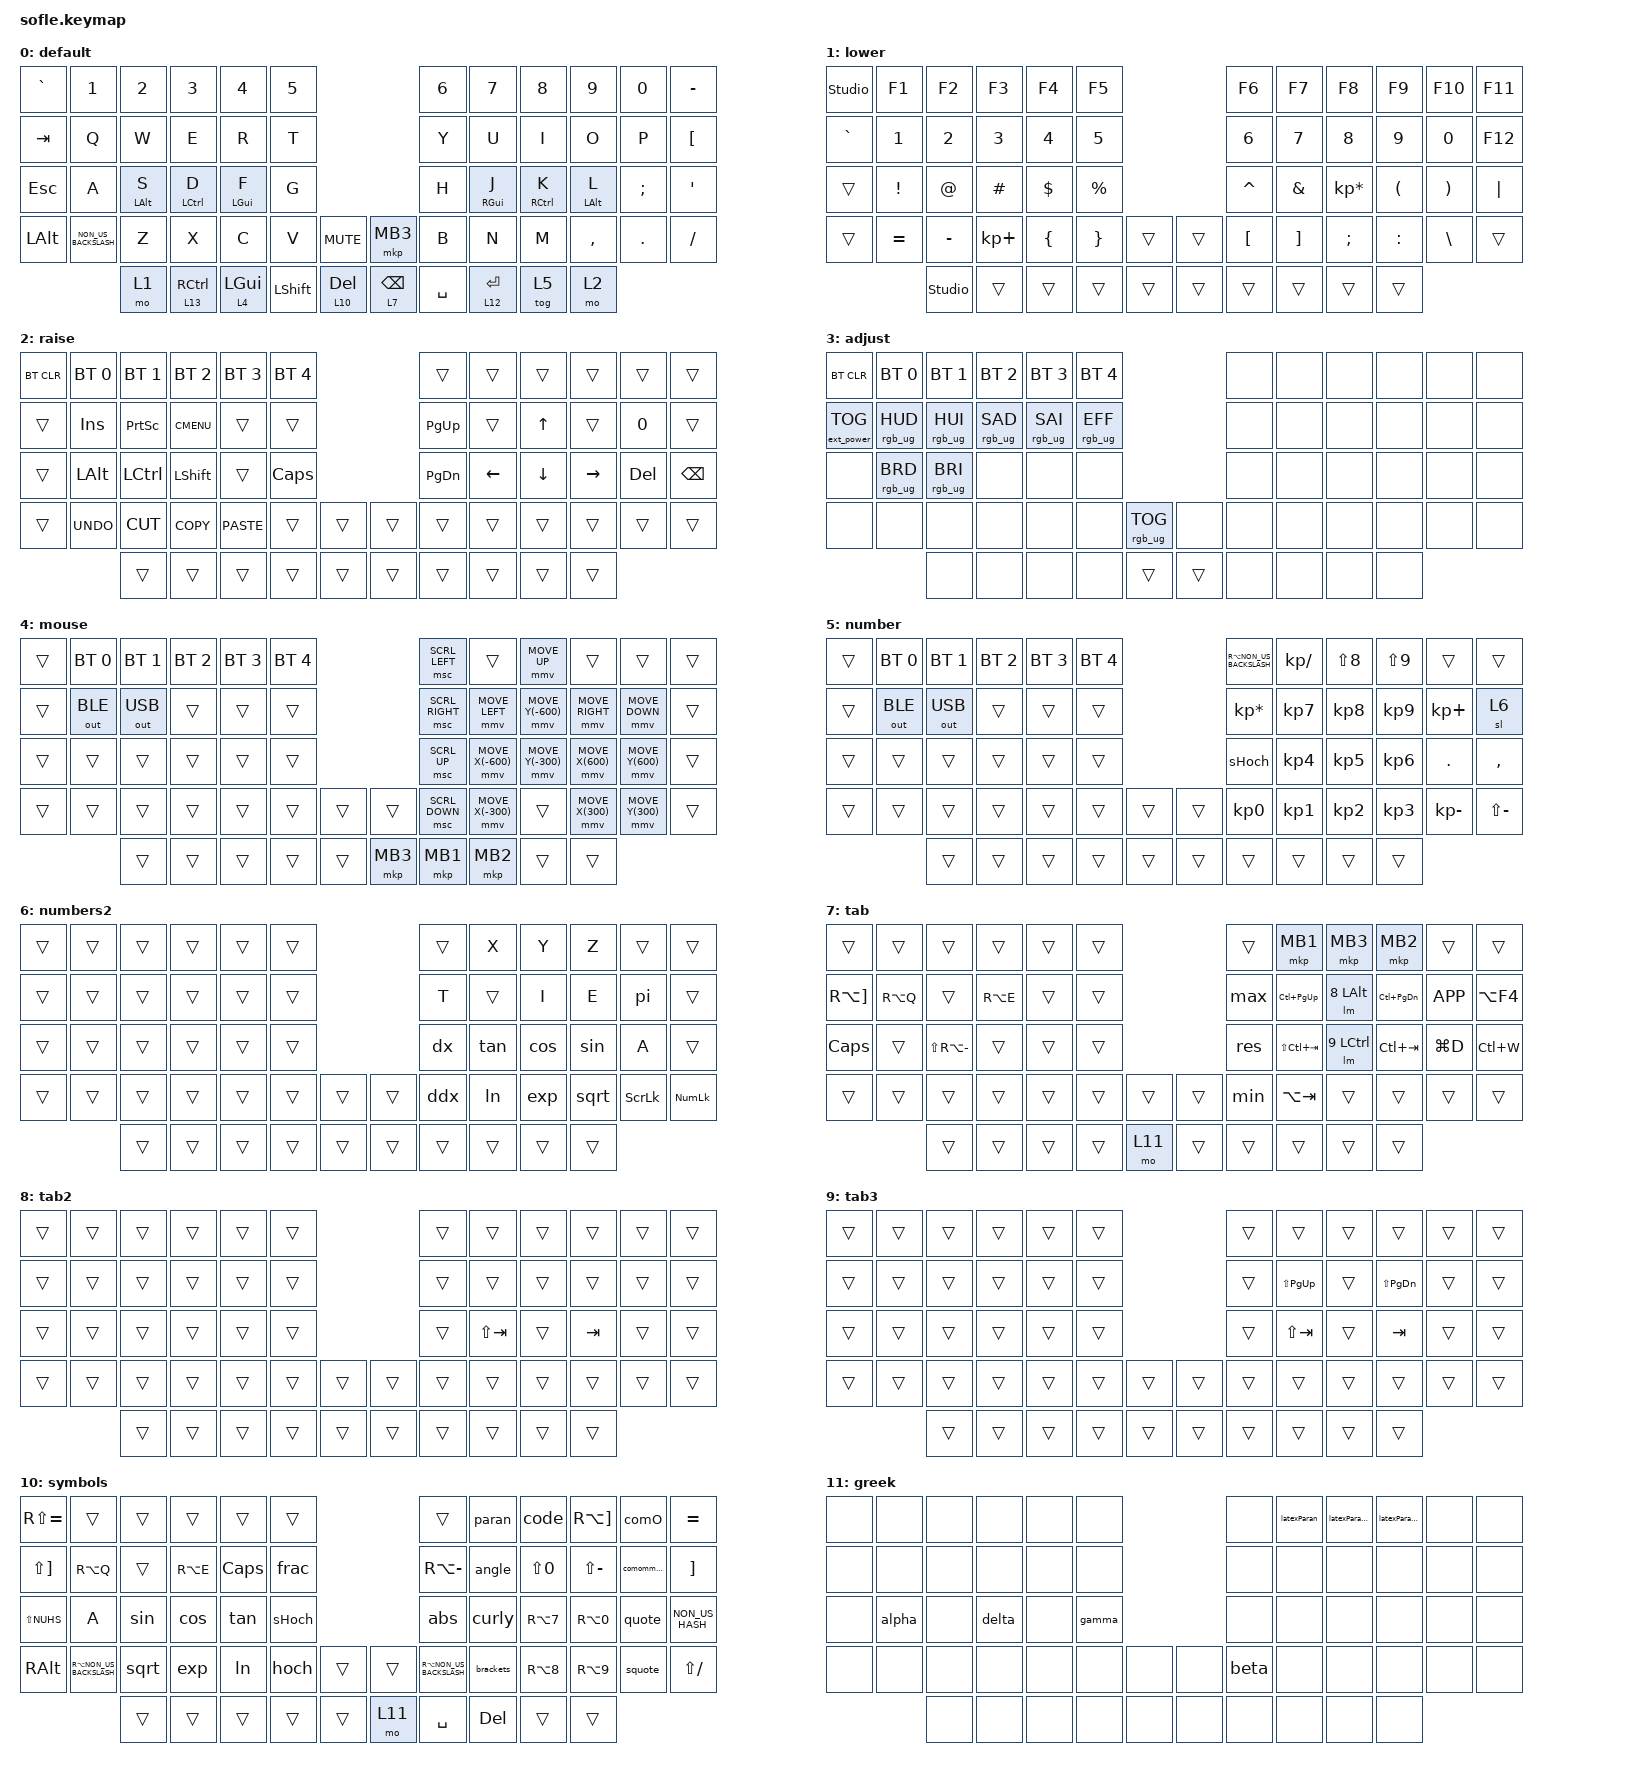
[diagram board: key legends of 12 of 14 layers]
/*
 * Copyright (c) 2020 The ZMK Contributors
 *
 * SPDX-License-Identifier: MIT
 */

#define ZMK_POINTING_DEFAULT_MOVE_VAL 1500  // default: 600
#define ZMK_POINTING_DEFAULT_SCRL_VAL 20    // default: 10

#include <behaviors.dtsi>
#include <dt-bindings/zmk/bt.h>
#include <dt-bindings/zmk/ext_power.h>
#include <dt-bindings/zmk/keys.h>
#include <dt-bindings/zmk/outputs.h>
#include <dt-bindings/zmk/pointing.h>
#include <dt-bindings/zmk/rgb.h>

#define BASE 0
#define LOWER 1
#define RAISE 2
#define ADJUST 3

&lt { flavor = "balanced"; };

/ {
    // Activate ADJUST layer by pressing raise and lower

    conditional_layers {
        compatible = "zmk,conditional-layers";

        adjust_layer {
            if-layers = <1 2>;
            then-layer = <3>;
        };
    };

    macros {
        lm: lm {
            compatible = "zmk,behavior-macro-two-param";
            #binding-cells = <2>;
            bindings =
                <&macro_param_1to1>,
                <&macro_press>,
                <&mo MACRO_PLACEHOLDER &macro_param_2to1>,
                <&macro_press>,
                <&kp MACRO_PLACEHOLDER>,
                <&macro_pause_for_release>,
                <&macro_param_2to1>,
                <&macro_release>,
                <&kp MACRO_PLACEHOLDER &macro_param_1to1>,
                <&macro_release>,
                <&mo MACRO_PLACEHOLDER>;

            label = "LM";
        };

        curly: curly {
            compatible = "zmk,behavior-macro";
            #binding-cells = <0>;
            bindings = <&kp RA(N7) &kp RA(N0) &kp LEFT>;
            label = "CURLY";
        };

        paran: paran {
            compatible = "zmk,behavior-macro";
            #binding-cells = <0>;
            bindings = <&kp LS(N8) &kp LS(N9) &kp LEFT>;
            label = "PARAN";
        };

        angle: angle {
            compatible = "zmk,behavior-macro";
            #binding-cells = <0>;
            bindings = <&kp NON_US_BACKSLASH &kp LS(NON_US_BACKSLASH) &kp LEFT>;
            label = "angle";
        };

        brackets: brackets {
            compatible = "zmk,behavior-macro";
            #binding-cells = <0>;
            bindings = <&kp RA(N8) &kp RA(N9) &kp LEFT>;
            label = "BRACKETS";
        };

        abs: abs {
            compatible = "zmk,behavior-macro";
            #binding-cells = <0>;
            bindings = <&kp RA(NON_US_BACKSLASH) &kp RA(NON_US_BACKSLASH) &kp LEFT>;
            label = "ABS";
        };

        comO: comO {
            compatible = "zmk,behavior-macro";
            #binding-cells = <0>;
            bindings = <&kp LS(N7) &kp LS(RIGHT_BRACKET)>;
            label = "COMO";
        };

        comommentClose: comC {
            compatible = "zmk,behavior-macro";
            #binding-cells = <0>;
            bindings = <&kp LS(RIGHT_BRACKET) &kp LS(N7)>;
            label = "COMC";
        };

        code: code {
            compatible = "zmk,behavior-macro";
            #binding-cells = <0>;
            bindings = <&kp LS(EQUAL) &kp LS(EQUAL) &kp LS(EQUAL) &kp SPACE>;
            label = "CODE";
        };

        quote: quote {
            compatible = "zmk,behavior-macro";
            #binding-cells = <0>;
            bindings = <&kp LS(N2) &kp LS(N2) &kp LEFT>;
            label = "QUOTE";
        };

        squote: squote {
            compatible = "zmk,behavior-macro";
            #binding-cells = <0>;
            bindings = <&kp LS(NON_US_HASH) &kp LS(NON_US_HASH) &kp LEFT>;
            label = "SQUOTE";
        };

        max: max {
            compatible = "zmk,behavior-macro";
            #binding-cells = <0>;
            bindings = <&kp LA(SPACE) &kp X>;
            label = "MAX";
        };

        min: min {
            compatible = "zmk,behavior-macro";
            #binding-cells = <0>;
            bindings = <&kp LA(SPACE) &kp N>;
            label = "MIN";
        };

        res: res {
            compatible = "zmk,behavior-macro";
            #binding-cells = <0>;
            bindings = <&kp LA(SPACE) &kp R>;
            label = "RES";
        };

        sin: sin {
            compatible = "zmk,behavior-macro";
            #binding-cells = <0>;
            bindings = <&kp S &kp I &kp N &kp LS(N8) &kp LS(N9) &kp LEFT>;
            label = "SIN";
        };

        cos: cos {
            compatible = "zmk,behavior-macro";
            #binding-cells = <0>;
            bindings = <&kp C &kp O &kp S &kp LS(N8) &kp LS(N9) &kp LEFT>;
            label = "COS";
        };

        tan: tan {
            compatible = "zmk,behavior-macro";
            #binding-cells = <0>;
            bindings = <&kp T &kp A &kp N &kp LS(N8) &kp LS(N9) &kp LEFT>;
            label = "TAN";
        };

        sqrt: sqrt {
            compatible = "zmk,behavior-macro";
            #binding-cells = <0>;
            bindings = <&kp S &kp Q &kp R &kp T &kp LS(N8) &kp LS(N9) &kp LEFT>;
            label = "SQRT";
        };

        hoch: hoch {
            compatible = "zmk,behavior-macro";
            #binding-cells = <0>;
            bindings = <&kp GRAVE &kp LS(N8) &kp LS(N9) &kp LEFT>;
            label = "HOCH";
        };

        exp: exp {
            compatible = "zmk,behavior-macro";
            #binding-cells = <0>;
            bindings = <&kp E &kp X &kp P &kp LS(N8) &kp LS(N9) &kp LEFT>;
            label = "EXP";
        };

        ln: ln {
            compatible = "zmk,behavior-macro";
            #binding-cells = <0>;
            bindings = <&kp L &kp N &kp LS(N8) &kp LS(N9) &kp LEFT>;
            label = "LN";
        };

        latexParanOpen: latexParanOpen {
            compatible = "zmk,behavior-macro";
            #binding-cells = <0>;
            bindings = <&kp RA(MINUS) &kp L &kp E &kp F &kp T &kp LS(N8)>;
            label = "LATEXPARAN";
        };

        latexParanClose: latexParanClose {
            compatible = "zmk,behavior-macro";
            #binding-cells = <0>;
            bindings = <&kp RA(MINUS) &kp R &kp I &kp G &kp H &kp T &kp LS(N9)>;
            label = "LATEXPARANCLOSE";
        };

        latexParan: latexParan {
            compatible = "zmk,behavior-macro";
            #binding-cells = <0>;
            bindings = <&kp RA(MINUS) &kp L &kp E &kp F &kp T &kp LS(N8) &kp RA(MINUS) &kp R &kp I &kp G &kp H &kp T &kp LS(N9) &kp LEFT_ARROW &kp LEFT_ARROW &kp LEFT_ARROW &kp LEFT_ARROW &kp LEFT &kp LEFT_ARROW &kp LEFT_ARROW>;
            label = "LATEXPARAN";
        };

        alpha: alpha {
            compatible = "zmk,behavior-macro";
            #binding-cells = <0>;
            bindings = <&kp RA(MINUS) &kp A &kp L &kp P &kp H &kp A>;
            label = "ALPHA";
        };

        beta: beta {
            compatible = "zmk,behavior-macro";
            #binding-cells = <0>;
            bindings = <&kp RA(MINUS) &kp B &kp E &kp T &kp A>;
            label = "BETA";
        };

        gamma: gamma {
            compatible = "zmk,behavior-macro";
            #binding-cells = <0>;
            bindings = <&kp RA(MINUS) &kp G &kp A &kp M &kp M &kp A>;
            label = "GAMMA";
        };

        delta: delta {
            compatible = "zmk,behavior-macro";
            #binding-cells = <0>;
            bindings = <&kp RA(MINUS) &kp D &kp E &kp L &kp T &kp A>;
            label = "DELTA";
        };

        sHoch: sHoch {
            compatible = "zmk,behavior-macro";
            #binding-cells = <0>;
            bindings = <&kp GRAVE &kp SPACE>;
            label = "SHOCH";
        };

        frac: frac {
            compatible = "zmk,behavior-macro";
            #binding-cells = <0>;
            bindings = <&kp RA(MINUS) &kp F &kp R &kp A &kp C &kp RA(N7) &kp RA(N0) &kp RA(N7) &kp RA(N0) &kp LEFT &kp LEFT_ARROW &kp LEFT_ARROW>;
            label = "FRAC";
        };

        pi: pi {
            compatible = "zmk,behavior-macro";
            #binding-cells = <0>;
            bindings = <&kp P &kp I>;
            label = "PI";
        };

        dx: dx {
            compatible = "zmk,behavior-macro";
            #binding-cells = <0>;
            bindings = <&kp D &kp X>;
            label = "DX";
        };

        ddx: ddx {
            compatible = "zmk,behavior-macro";
            #binding-cells = <0>;
            bindings = <&kp D &kp LS(N7) &kp D &kp X>;
            label = "DDX";
        };
    };

    behaviors {
        MoTapHp: MoTapHp {
            compatible = "zmk,behavior-hold-tap";
            label = "MOTAPHP";
            bindings = <&mo>, <&kp>;

            #binding-cells = <2>;
            tapping-term-ms = <280>;
            quick-tap-ms = <175>;
            flavor = "hold-preferred";
            hold-trigger-key-positions = <20 32 18 30 44 19 31 33 34 7 9 8 21 23 35 54 24 12 13 15 26 45>;
        };

        HRM_L: HRM_L {
            compatible = "zmk,behavior-hold-tap";
            label = "HRM_L";
            bindings = <&kp>, <&kp>;

            #binding-cells = <2>;
            tapping-term-ms = <280>;
            quick-tap-ms = <175>;
            require-prior-idle-ms = <150>;
            flavor = "balanced";
            hold-trigger-key-positions = <57 56 55 53 0 1 2 3 4 5 12 13 14 15 16 17 24 25 26 27 28 29 36 37 38 39 40 41 42>;
            hold-trigger-on-release;
        };

        HRM_R: HRM_R {
            compatible = "zmk,behavior-hold-tap";
            label = "HRM_R";
            bindings = <&kp>, <&kp>;

            #binding-cells = <2>;
            tapping-term-ms = <280>;
            quick-tap-ms = <175>;
            require-prior-idle-ms = <150>;
            flavor = "balanced";
            hold-trigger-key-positions = <57 56 55 53 6 7 8 9 10 11 18 19 20 21 22 23 30 31 32 33 34 35 43 44 45 46 47 48 49>;
            hold-trigger-on-release;
        };

        MoTap: MoTap {
            compatible = "zmk,behavior-hold-tap";
            label = "MOTAP";
            bindings = <&mo>, <&kp>;

            #binding-cells = <2>;
            tapping-term-ms = <280>;
            quick-tap-ms = <175>;
            require-prior-idle-ms = <150>;
            flavor = "balanced";
        };

        nav_word: nav_word {
            compatible = "zmk,behavior-auto-layer";
            #binding-cells = <1>;
            continue-list = <LEFT DOWN UP RIGHT PG_DN PG_UP HOME END TAB>;
            ignore-modifiers;
        };

        navWord: navWord {
            compatible = "zmk,behavior-hold-tap";
            label = "NAVWORD";
            bindings = <&nav_word>, <&kp>;

            #binding-cells = <2>;
            tapping-term-ms = <280>;
            quick-tap-ms = <175>;
            require-prior-idle-ms = <150>;
            flavor = "balanced";
        };

        ms_word: ms_word {
            compatible = "zmk,behavior-auto-layer";
            #binding-cells = <1>;
            continue-list = <LEFT DOWN UP RIGHT PG_DN PG_UP HOME END TAB>;
            ignore-modifiers;
        };

        msWord: msWord {
            compatible = "zmk,behavior-hold-tap";
            label = "MSWORD";
            bindings = <&ms_word>, <&kp>;

            #binding-cells = <2>;
            tapping-term-ms = <280>;
            quick-tap-ms = <175>;
            require-prior-idle-ms = <150>;
            flavor = "balanced";
        };
    };

    combos { compatible = "zmk,combos"; };

    keymap {
        compatible = "zmk,keymap";

        default_layer {
            label = "default";

            // ------------------------------------------------------------------------------------------------------------
            // |   `   |  1  |  2  |  3   |  4   |  5   |                   |  6   |  7    |  8    |  9   |   0   |       |
            // |  ESC  |  Q  |  W  |  E   |  R   |  T   |                   |  Y   |  U    |  I    |  O   |   P   | BKSPC |
            // |  TAB  |  A  |  S  |  D   |  F   |  G   |                   |  H   |  J    |  K    |  L   |   ;   |   '   |
            // | SHIFT |  Z  |  X  |  C   |  V   |  B   |  MUTE  |  |       |  N   |  M    |  ,    |  .   |   /   | SHIFT |
            //               | GUI | ALT  | CTRL | LOWER|  ENTER |  | SPACE | RAISE| CTRL  | ALT   | GUI  |

            bindings = <
&kp GRAVE     &kp N1                &kp N2             &kp N3           &kp N4             &kp N5                                                 &kp N6     &kp N7              &kp N8          &kp N9             &kp N0         &kp MINUS
&kp TAB       &kp Q                 &kp W              &kp E            &kp R              &kp T                                                  &kp Y      &kp U               &kp I           &kp O              &kp P          &kp LEFT_BRACKET
&kp ESC       &kp A                 &HRM_R LEFT_ALT S  &HRM_R LCTRL D   &HRM_R LEFT_GUI F  &kp G                                                  &kp H      &HRM_L RIGHT_GUI J  &HRM_L RCTRL K  &HRM_L LEFT_ALT L  &kp SEMICOLON  &kp SQT
&kp LEFT_ALT  &kp NON_US_BACKSLASH  &kp Z              &kp X            &kp C              &kp V           &kp K_MUTE       &mkp MB3              &kp B      &kp N               &kp M           &kp COMMA          &kp PERIOD     &kp SLASH
                                    &mo 1              &MoTap 13 RCTRL  &MoTap 4 LGUI      &kp LEFT_SHIFT  &MoTap 10 DEL    &MoTapHp 7 BACKSPACE  &kp SPACE  &MoTap 12 ENTER     &tog 5          &mo 2
            >;

            sensor-bindings =
                <&inc_dec_kp C_VOLUME_DOWN C_VOL_UP>,
                <&inc_dec_kp K_SCROLL_UP K_SCROLL_DOWN>;
        };

        lower_layer {
            label = "lower";

            // TODO: Some binds are waiting for shifted keycode support.
            // ------------------------------------------------------------------------------------------------------------
            // |       |  F1 |  F2 |  F3  |  F4  |  F5  |                   |  F6  |  F7   |  F8   |  F9  |  F10  |  F11  |
            // |   `   |  1  |  2  |  3   |  4   |  5   |                   |  6   |  7    |  8    |  9   |   0   |  F12  |
            // |       |  !  |  @  |  #   |  $   |  %   |                   |  ^   |  &    |  *    |  (   |   )   |   |   |
            // |       |  =  |  -  |  +   |  {   |  }   |        |  |       |  [   |  ]    |  ;    |  :   |   \   |       |
            //               |     |      |      |      |        |  |       |      |       |       |      |

            bindings = <
&studio_unlock  &kp F1     &kp F2          &kp F3       &kp F4    &kp F5                       &kp F6     &kp F7    &kp F8           &kp F9     &kp F10   &kp F11
&kp GRAVE       &kp N1     &kp N2          &kp N3       &kp N4    &kp N5                       &kp N6     &kp N7    &kp N8           &kp N9     &kp N0    &kp F12
&trans          &kp EXCL   &kp AT          &kp HASH     &kp DLLR  &kp PRCNT                    &kp CARET  &kp AMPS  &kp KP_MULTIPLY  &kp LPAR   &kp RPAR  &kp PIPE
&trans          &kp EQUAL  &kp MINUS       &kp KP_PLUS  &kp LBRC  &kp RBRC   &trans    &trans  &kp LBKT   &kp RBKT  &kp SEMI         &kp COLON  &kp BSLH  &trans
                           &studio_unlock  &trans       &trans    &trans     &trans    &trans  &trans     &trans    &trans           &trans
            >;

            sensor-bindings = <&inc_dec_kp C_VOL_UP C_VOL_DN &inc_dec_kp PG_UP PG_DN>;
        };

        raise_layer {
            label = "raise";

            // ------------------------------------------------------------------------------------------------------------
            // | BTCLR | BT1  | BT2  |  BT3  |  BT4  |  BT5 |                |      |      |       |      |       |       |
            // |       | INS  | PSCR | GUI   |       |      |                | PGUP |      |   ^   |      |       |       |
            // |       | ALT  | CTRL | SHIFT |       | CAPS |                | PGDN |   <- |   v   |  ->  |  DEL  | BKSPC |
            // |       | UNDO | CUT  | COPY  | PASTE |      |      |  |      |      |      |       |      |       |       |
            //                |      |       |       |      |      |  |      |      |      |       |      |

            bindings = <
&bt BT_CLR  &bt BT_SEL 0  &bt BT_SEL 1  &bt BT_SEL 2  &bt BT_SEL 3  &bt BT_SEL 4                    &trans     &trans    &trans    &trans     &trans   &trans
&trans      &kp INS       &kp PSCRN     &kp K_CMENU   &trans        &trans                          &kp PG_UP  &trans    &kp UP    &trans     &kp N0   &trans
&trans      &kp LALT      &kp LCTRL     &kp LSHFT     &trans        &kp CLCK                        &kp PG_DN  &kp LEFT  &kp DOWN  &kp RIGHT  &kp DEL  &kp BSPC
&trans      &kp K_UNDO    &kp K_CUT     &kp K_COPY    &kp K_PASTE   &trans        &trans    &trans  &trans     &trans    &trans    &trans     &trans   &trans
                          &trans        &trans        &trans        &trans        &trans    &trans  &trans     &trans    &trans    &trans
            >;

            sensor-bindings = <&inc_dec_kp C_VOL_UP C_VOL_DN &inc_dec_kp PG_UP PG_DN>;
        };

        adjust_layer {
            // ----------------------------------------------------------------------------------------------------------------------------
            // | BTCLR  |  BT1    |  BT2    |   BT3   |   BT4   |   BT5   |                  |      |      |       |      |       |       |
            // | EXTPWR | RGB_HUD | RGB_HUI | RGB_SAD | RGB_SAI | RGB_EFF |                  |      |      |       |      |       |       |
            // |        | RGB_BRD | RGB_BRI |         |         |         |                  |      |      |       |      |       |       |
            // |        |         |         |         |         |         | RGB_TOG | |      |      |      |       |      |       |       |
            //                    |         |         |         |         |         | |      |      |      |       |      |

            label = "adjust";
            bindings = <
&bt BT_CLR         &bt BT_SEL 0     &bt BT_SEL 1     &bt BT_SEL 2     &bt BT_SEL 3     &bt BT_SEL 4                                &none  &none  &none  &none  &none  &none
&ext_power EP_TOG  &rgb_ug RGB_HUD  &rgb_ug RGB_HUI  &rgb_ug RGB_SAD  &rgb_ug RGB_SAI  &rgb_ug RGB_EFF                             &none  &none  &none  &none  &none  &none
&none              &rgb_ug RGB_BRD  &rgb_ug RGB_BRI  &none            &none            &none                                       &none  &none  &none  &none  &none  &none
&none              &none            &none            &none            &none            &none            &rgb_ug RGB_TOG    &none   &none  &none  &none  &none  &none  &none
                                    &none            &none            &none            &none            &trans             &trans  &none  &none  &none  &none
            >;
        };

        mouse {
            bindings = <
&trans  &bt BT_SEL 0  &bt BT_SEL 1  &bt BT_SEL 2  &bt BT_SEL 3  &bt BT_SEL 4                      &msc SCRL_LEFT   &trans             &mmv MOVE_UP       &trans            &trans            &trans
&trans  &out OUT_BLE  &out OUT_USB  &trans        &trans        &trans                            &msc SCRL_RIGHT  &mmv MOVE_LEFT     &mmv MOVE_Y(-600)  &mmv MOVE_RIGHT   &mmv MOVE_DOWN    &trans
&trans  &trans        &trans        &trans        &trans        &trans                            &msc SCRL_UP     &mmv MOVE_X(-600)  &mmv MOVE_Y(-300)  &mmv MOVE_X(600)  &mmv MOVE_Y(600)  &trans
&trans  &trans        &trans        &trans        &trans        &trans        &trans    &trans    &msc SCRL_DOWN   &mmv MOVE_X(-300)  &trans             &mmv MOVE_X(300)  &mmv MOVE_Y(300)  &trans
                      &trans        &trans        &trans        &trans        &trans    &mkp MB3  &mkp MB1         &mkp MB2           &trans             &trans
            >;

            label = "mouse";
        };

        number {
            label = "number";
            bindings = <
&trans  &bt BT_SEL 0  &bt BT_SEL 1  &bt BT_SEL 2  &bt BT_SEL 3  &bt BT_SEL 4                    &kp RA(NON_US_BACKSLASH)  &kp KP_DIVIDE    &kp LS(N8)       &kp LS(N9)       &trans        &trans
&trans  &out OUT_BLE  &out OUT_USB  &trans        &trans        &trans                          &kp KP_MULTIPLY           &kp KP_NUMBER_7  &kp KP_NUMBER_8  &kp KP_NUMBER_9  &kp KP_PLUS   &sl 6
&trans  &trans        &trans        &trans        &trans        &trans                          &sHoch                    &kp KP_NUMBER_4  &kp KP_NUMBER_5  &kp KP_NUMBER_6  &kp PERIOD    &kp COMMA
&trans  &trans        &trans        &trans        &trans        &trans        &trans    &trans  &kp KP_NUMBER_0           &kp KP_NUMBER_1  &kp KP_NUMBER_2  &kp KP_NUMBER_3  &kp KP_MINUS  &kp LS(MINUS)
                      &trans        &trans        &trans        &trans        &trans    &trans  &trans                    &trans           &trans           &trans
            >;
        };

        numbers2 {
            bindings = <
&trans  &trans  &trans  &trans  &trans  &trans                    &trans  &kp X   &kp Y   &kp Z   &trans          &trans
&trans  &trans  &trans  &trans  &trans  &trans                    &kp T   &trans  &kp I   &kp E   &pi             &trans
&trans  &trans  &trans  &trans  &trans  &trans                    &dx     &tan    &cos    &sin    &kp A           &trans
&trans  &trans  &trans  &trans  &trans  &trans  &trans    &trans  &ddx    &ln     &exp    &sqrt   &kp SCROLLLOCK  &kp KP_NUM
                &trans  &trans  &trans  &trans  &trans    &trans  &trans  &trans  &trans  &trans
            >;

            label = "numbers2";
        };

        tab {
            bindings = <
&trans                 &trans     &trans             &trans     &trans  &trans                    &trans  &mkp MB1         &mkp MB3     &mkp MB2           &trans     &trans
&kp RA(RIGHT_BRACKET)  &kp RA(Q)  &trans             &kp RA(E)  &trans  &trans                    &max    &kp LC(PG_UP)    &lm 8 LALT   &kp LC(PAGE_DOWN)  &kp K_APP  &kp LA(F4)
&kp CAPS               &trans     &kp LS(RA(MINUS))  &trans     &trans  &trans                    &res    &kp LS(LC(TAB))  &lm 9 LCTRL  &kp LC(TAB)        &kp LG(D)  &kp LC(W)
&trans                 &trans     &trans             &trans     &trans  &trans  &trans    &trans  &min    &kp LA(TAB)      &trans       &trans             &trans     &trans
                                  &trans             &trans     &trans  &trans  &mo 11    &trans  &trans  &trans           &trans       &trans
            >;

            label = "tab";
        };

        tab2 {
            bindings = <
&trans  &trans  &trans  &trans  &trans  &trans                    &trans  &trans       &trans  &trans   &trans  &trans
&trans  &trans  &trans  &trans  &trans  &trans                    &trans  &trans       &trans  &trans   &trans  &trans
&trans  &trans  &trans  &trans  &trans  &trans                    &trans  &kp LS(TAB)  &trans  &kp TAB  &trans  &trans
&trans  &trans  &trans  &trans  &trans  &trans  &trans    &trans  &trans  &trans       &trans  &trans   &trans  &trans
                &trans  &trans  &trans  &trans  &trans    &trans  &trans  &trans       &trans  &trans
            >;

            label = "tab2";
        };

        tab3 {
            label = "tab3";
            bindings = <
&trans  &trans  &trans  &trans  &trans  &trans                    &trans  &trans         &trans  &trans         &trans  &trans
&trans  &trans  &trans  &trans  &trans  &trans                    &trans  &kp LS(PG_UP)  &trans  &kp LS(PG_DN)  &trans  &trans
&trans  &trans  &trans  &trans  &trans  &trans                    &trans  &kp LS(TAB)    &trans  &kp TAB        &trans  &trans
&trans  &trans  &trans  &trans  &trans  &trans  &trans    &trans  &trans  &trans         &trans  &trans         &trans  &trans
                &trans  &trans  &trans  &trans  &trans    &trans  &trans  &trans         &trans  &trans
            >;
        };

        symbols {
            bindings = <
&kp RS(EQUAL)          &trans                    &trans  &trans     &trans    &trans                    &trans                    &paran     &code       &kp RA(RIGHT_BRACKET)  &comO            &kp EQUAL
&kp LS(RIGHT_BRACKET)  &kp RA(Q)                 &trans  &kp RA(E)  &kp CAPS  &frac                     &kp RA(MINUS)             &angle     &kp LS(N0)  &kp LS(MINUS)          &comommentClose  &kp RIGHT_BRACKET
&kp LS(NUHS)           &kp A                     &sin    &cos       &tan      &sHoch                    &abs                      &curly     &kp RA(N7)  &kp RA(N0)             &quote           &kp NON_US_HASH
&kp RALT               &kp RA(NON_US_BACKSLASH)  &sqrt   &exp       &ln       &hoch   &trans    &trans  &kp RA(NON_US_BACKSLASH)  &brackets  &kp RA(N8)  &kp RA(N9)             &squote          &kp LS(SLASH)
                                                 &trans  &trans     &trans    &trans  &trans    &mo 11  &kp SPACE                 &kp DEL    &trans      &trans
            >;

            label = "symbols";
        };

        greek {
            bindings = <
&none  &none   &none  &none   &none  &none                   &none  &latexParan  &latexParanOpen  &latexParanClose  &none  &none
&none  &none   &none  &none   &none  &none                   &none  &none        &none            &none             &none  &none
&none  &alpha  &none  &delta  &none  &gamma                  &none  &none        &none            &none             &none  &none
&none  &none   &none  &none   &none  &none   &none    &none  &beta  &none        &none            &none             &none  &none
               &none  &none   &none  &none   &none    &none  &none  &none        &none            &none
            >;

            label = "greek";
        };

        nav {
            bindings = <
&trans  &trans  &trans  &trans  &trans  &trans                    &trans     &kp LC(HOME)   &kp K_APPLICATION  &kp LC(END)    &trans     &kp INS
&trans  &trans  &trans  &trans  &trans  &trans                    &kp HOME   &kp LC(LEFT)   &kp UP_ARROW       &kp LC(RIGHT)  &kp END    &kp LC(V)
&trans  &trans  &trans  &trans  &trans  &trans                    &kp PG_UP  &kp LEFT       &kp LS(TAB)        &kp RIGHT      &kp DOWN   &kp TAB
&trans  &trans  &trans  &trans  &trans  &trans  &trans    &trans  &kp PG_DN  &kp BACKSPACE  &kp DEL            &kp LC(A)      &kp LC(X)  &kp LC(C)
                &trans  &trans  &trans  &trans  &trans    &trans  &trans     &trans         &trans             &trans
            >;

            label = "nav";
        };

        media {
            bindings = <
&trans  &trans      &trans      &trans            &trans      &trans                          &trans  &kp F10  &kp F11  &kp F12  &trans  &trans
&trans  &trans      &trans      &trans            &trans      &kp C_VOL_UP                    &trans  &kp F7   &kp F8   &kp F9   &trans  &trans
&trans  &kp K_STOP  &kp K_PREV  &kp K_PLAY_PAUSE  &kp K_NEXT  &kp K_MUTE                      &trans  &kp F4   &kp F5   &kp F6   &trans  &trans
&trans  &trans      &trans      &trans            &trans      &kp C_VOL_DN  &trans    &trans  &trans  &kp F1   &kp F2   &kp F3   &trans  &trans
                    &trans      &trans            &trans      &trans        &trans    &trans  &trans  &trans   &trans   &trans
            >;

            label = "media";
        };
    };
};
